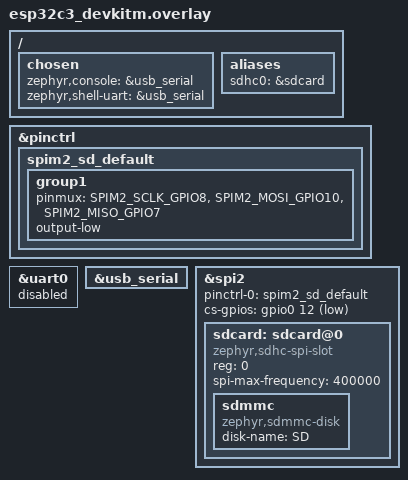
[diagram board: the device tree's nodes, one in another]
/*
 * Diagnostic-only XTEINK X4 SPI SD-card smoke-test overlay.
 *
 * This checks the target's built-in microSD wiring without enabling
 * SquidScript SD storage. The card shares SPI2 with the e-paper panel.
 */

#include <zephyr/dt-bindings/gpio/gpio.h>
#include <zephyr/dt-bindings/pinctrl/esp32c3-pinctrl.h>

/ {
	chosen {
		zephyr,console = &usb_serial;
		zephyr,shell-uart = &usb_serial;
	};

	/delete-node/ gpio_keys;

	aliases {
		/delete-property/ sw0;
		sdhc0 = &sdcard;
	};
};

&pinctrl {
	spim2_sd_default: spim2_sd_default {
		group1 {
			pinmux = <SPIM2_SCLK_GPIO8>,
				 <SPIM2_MOSI_GPIO10>,
				 <SPIM2_MISO_GPIO7>;
			output-low;
		};
	};
};

&uart0 {
	status = "disabled";
};

&usb_serial {
	status = "okay";
};

&spi2 {
	status = "okay";
	pinctrl-0 = <&spim2_sd_default>;
	pinctrl-names = "default";
	cs-gpios = <&gpio0 12 GPIO_ACTIVE_LOW>;

	sdcard: sdcard@0 {
		compatible = "zephyr,sdhc-spi-slot";
		reg = <0>;
		status = "okay";
		spi-max-frequency = <400000>;

		sdmmc {
			compatible = "zephyr,sdmmc-disk";
			disk-name = "SD";
			status = "okay";
		};
	};
};
